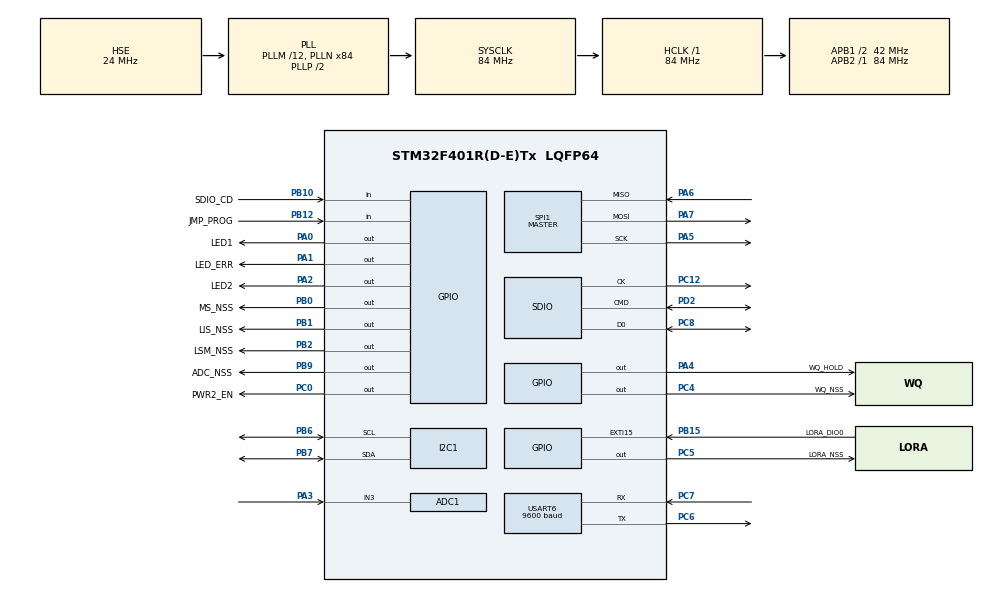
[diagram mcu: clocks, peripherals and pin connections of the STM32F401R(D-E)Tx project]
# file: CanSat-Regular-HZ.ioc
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ADC1.Channel-0\#ChannelRegularConversion=ADC_CHANNEL_3
ADC1.ContinuousConvMode=DISABLE
ADC1.NbrOfConversionFlag=1
ADC1.Rank-0\#ChannelRegularConversion=1
ADC1.Resolution=ADC_RESOLUTION_8B
ADC1.SamplingTime-0\#ChannelRegularConversion=ADC_SAMPLETIME_3CYCLES
ADC1.master=1
Dma.Request0=SDIO_RX
Dma.Request1=SDIO_TX
Dma.SDIO_RX.0.Direction=DMA_PERIPH_TO_MEMORY
Dma.SDIO_RX.0.FIFOMode=DMA_FIFOMODE_ENABLE
Dma.SDIO_RX.0.FIFOThreshold=DMA_FIFO_THRESHOLD_FULL
Dma.SDIO_RX.0.Instance=DMA2_Stream3
Dma.SDIO_RX.0.MemBurst=DMA_MBURST_INC4
Dma.SDIO_RX.0.MemDataAlignment=DMA_MDATAALIGN_WORD
Dma.SDIO_RX.0.MemInc=DMA_MINC_ENABLE
Dma.SDIO_RX.0.Mode=DMA_PFCTRL
Dma.SDIO_RX.0.PeriphBurst=DMA_PBURST_INC4
Dma.SDIO_RX.0.PeriphDataAlignment=DMA_PDATAALIGN_WORD
Dma.SDIO_RX.0.PeriphInc=DMA_PINC_DISABLE
Dma.SDIO_RX.0.Priority=DMA_PRIORITY_LOW
Dma.SDIO_TX.1.Direction=DMA_MEMORY_TO_PERIPH
Dma.SDIO_TX.1.FIFOMode=DMA_FIFOMODE_ENABLE
Dma.SDIO_TX.1.FIFOThreshold=DMA_FIFO_THRESHOLD_FULL
Dma.SDIO_TX.1.Instance=DMA2_Stream6
Dma.SDIO_TX.1.MemBurst=DMA_MBURST_INC4
Dma.SDIO_TX.1.MemDataAlignment=DMA_MDATAALIGN_WORD
Dma.SDIO_TX.1.MemInc=DMA_MINC_ENABLE
Dma.SDIO_TX.1.Mode=DMA_PFCTRL
Dma.SDIO_TX.1.PeriphBurst=DMA_PBURST_INC4
Dma.SDIO_TX.1.PeriphDataAlignment=DMA_PDATAALIGN_WORD
Dma.SDIO_TX.1.PeriphInc=DMA_PINC_DISABLE
Dma.SDIO_TX.1.Priority=DMA_PRIORITY_LOW
FATFS.BSP.number=1
FATFS.USE_DMA_CODE_SD=1
FATFS._FS_TIMEOUT=1000
FATFS0.BSP.STBoard=false
FATFS0.BSP.api=Unknown
FATFS0.BSP.instance=PB10
FATFS0.BSP.ip=GPIO
FATFS0.BSP.mode=Input
FATFS0.BSP.name=Detect_SDIO
FATFS0.BSP.solution=PB10
Mcu.Family=STM32F4
Mcu.Name=STM32F401R(D-E)Tx
Mcu.Package=LQFP64
NVIC.DMA2_Stream3_IRQn=true\:0\:0\:false\:false\:true\:false\:true\:true
NVIC.DMA2_Stream6_IRQn=true\:0\:0\:false\:false\:true\:false\:true\:true
NVIC.EXTI15_10_IRQn=true\:0\:0\:false\:false\:true\:true\:true\:true
NVIC.PriorityGroup=NVIC_PRIORITYGROUP_4
NVIC.SDIO_IRQn=true\:0\:0\:false\:false\:true\:true\:true\:true
NVIC.USART6_IRQn=true\:0\:0\:false\:false\:true\:true\:true\:true
PA0-WKUP.GPIO_Label=LED1
PA0-WKUP.PinState=GPIO_PIN_RESET
PA0-WKUP.Signal=GPIO_Output
PA1.GPIO_Label=LED_ERR
PA1.Signal=GPIO_Output
PA2.GPIO_Label=LED2
PA2.Signal=GPIO_Output
PA3.Signal=ADCx_IN3
PA4.GPIO_Label=WQ_HOLD
PA4.PinState=GPIO_PIN_SET
PA4.Signal=GPIO_Output
PA5.Mode=Full_Duplex_Master
PA5.Signal=SPI1_SCK
PA6.Mode=Full_Duplex_Master
PA6.Signal=SPI1_MISO
PA7.Mode=Full_Duplex_Master
PA7.Signal=SPI1_MOSI
PB0.GPIO_Label=MS_NSS
PB0.GPIO_Speed=GPIO_SPEED_FREQ_VERY_HIGH
PB0.PinState=GPIO_PIN_SET
PB0.Signal=GPIO_Output
PB1.GPIO_Label=LIS_NSS
PB1.GPIO_Speed=GPIO_SPEED_FREQ_VERY_HIGH
PB1.PinState=GPIO_PIN_SET
PB1.Signal=GPIO_Output
PB10.GPIO_Label=SDIO_CD
PB10.Signal=GPIO_Input
PB12.GPIO_Label=JMP_PROG
PB12.Signal=GPIO_Input
PB15.GPIO_Label=LORA_DIO0
PB15.Signal=GPXTI15
PB2.GPIO_Label=LSM_NSS
PB2.GPIO_Speed=GPIO_SPEED_FREQ_VERY_HIGH
PB2.PinState=GPIO_PIN_SET
PB2.Signal=GPIO_Output
PB6.Mode=I2C
PB6.Signal=I2C1_SCL
PB7.Mode=I2C
PB7.Signal=I2C1_SDA
PB9.GPIO_Label=ADC_NSS
PB9.GPIO_Speed=GPIO_SPEED_FREQ_VERY_HIGH
PB9.PinState=GPIO_PIN_SET
PB9.Signal=GPIO_Output
PC0.GPIO_Label=PWR2_EN
PC0.PinState=GPIO_PIN_SET
PC0.Signal=GPIO_Output
PC12.Mode=SD_1_bit
PC12.Signal=SDIO_CK
PC14-OSC32_IN.Mode=LSE-External-Oscillator
PC14-OSC32_IN.Signal=RCC_OSC32_IN
PC15-OSC32_OUT.Mode=LSE-External-Oscillator
PC15-OSC32_OUT.Signal=RCC_OSC32_OUT
PC4.GPIO_Label=WQ_NSS
PC4.GPIO_Speed=GPIO_SPEED_FREQ_VERY_HIGH
PC4.PinState=GPIO_PIN_SET
PC4.Signal=GPIO_Output
PC5.GPIO_Label=LORA_NSS
PC5.GPIO_Speed=GPIO_SPEED_FREQ_VERY_HIGH
PC5.PinState=GPIO_PIN_SET
PC5.Signal=GPIO_Output
PC6.Mode=Asynchronous
PC6.Signal=USART6_TX
PC7.Mode=Asynchronous
PC7.Signal=USART6_RX
PC8.GPIO_PuPd=GPIO_PULLUP
PC8.Mode=SD_1_bit
PC8.Signal=SDIO_D0
PD2.GPIO_PuPd=GPIO_PULLUP
PD2.Mode=SD_1_bit
PD2.Signal=SDIO_CMD
PH0\ -\ OSC_IN.Mode=HSE-External-Oscillator
PH0\ -\ OSC_IN.Signal=RCC_OSC_IN
PH1\ -\ OSC_OUT.Mode=HSE-External-Oscillator
PH1\ -\ OSC_OUT.Signal=RCC_OSC_OUT
ProjectManager.HeapSize=0x200
ProjectManager.StackSize=0x400
ProjectManager.TargetToolchain=STM32CubeIDE
RCC.48MHZClocksFreq_Value=42000000
RCC.AHBFreq_Value=84000000
RCC.APB1CLKDivider=RCC_HCLK_DIV2
RCC.APB1Freq_Value=42000000
RCC.APB1TimFreq_Value=84000000
RCC.APB2Freq_Value=84000000
RCC.APB2TimFreq_Value=84000000
RCC.CortexFreq_Value=84000000
RCC.HCLKFreq_Value=84000000
RCC.HSE_VALUE=24000000
RCC.HSI_VALUE=16000000
RCC.PLLM=12
RCC.PLLN=84
RCC.PLLSourceVirtual=RCC_PLLSOURCE_HSE
RCC.SYSCLKFreq_VALUE=84000000
RCC.SYSCLKSource=RCC_SYSCLKSOURCE_PLLCLK
RCC.VCOOutputFreq_Value=168000000
SDIO.ClockDiv=6
SDIO.HardwareFlowControl=SDIO_HARDWARE_FLOW_CONTROL_ENABLE
SH.ADCx_IN3.0=ADC1_IN3,IN3
SPI1.BaudRatePrescaler=SPI_BAUDRATEPRESCALER_16
SPI1.CLKPhase=SPI_PHASE_1EDGE
SPI1.Direction=SPI_DIRECTION_2LINES
SPI1.Mode=SPI_MODE_MASTER
SPI1.VirtualType=VM_MASTER
USART6.BaudRate=9600
USART6.VirtualMode=VM_ASYNC
VP_FATFS_VS_SDIO.Mode=SDIO
board=custom

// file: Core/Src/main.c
/* USER CODE BEGIN Header */
/**
  ******************************************************************************
  * @file           : main.c
  * @brief          : Main program body
  ******************************************************************************
  * @attention
  *
  * Copyright (c) 2025 STMicroelectronics.
  * All rights reserved.
  *
  * This software is licensed under terms that can be found in the LICENSE file
  * in the root directory of this software component.
  * If no LICENSE file comes with this software, it is provided AS-IS.
  *
  ******************************************************************************
  */
/* USER CODE END Header */
#include "main.h"
#include "fatfs.h"

/* USER CODE BEGIN Includes */
#include "FSM.h"
/* USER CODE END Includes */

ADC_HandleTypeDef hadc1;

I2C_HandleTypeDef hi2c1;

SD_HandleTypeDef hsd;
DMA_HandleTypeDef hdma_sdio_rx;
DMA_HandleTypeDef hdma_sdio_tx;

SPI_HandleTypeDef hspi1;

UART_HandleTypeDef huart6;

void SystemClock_Config(void);
static void MX_GPIO_Init(void);
static void MX_DMA_Init(void);
static void MX_I2C1_Init(void);
static void MX_SPI1_Init(void);
static void MX_ADC1_Init(void);
static void MX_SDIO_SD_Init(void);
static void MX_USART6_UART_Init(void);

int main(void)
{

  /* MCU Configuration--------------------------------------------------------*/

  /* Reset of all peripherals, Initializes the Flash interface and the Systick. */
  HAL_Init();

  /* Configure the system clock */
  SystemClock_Config();

  /* Initialize all configured peripherals */
  MX_GPIO_Init();
  MX_DMA_Init();
  MX_I2C1_Init();
  MX_SPI1_Init();
  MX_ADC1_Init();
  MX_SDIO_SD_Init();
  MX_FATFS_Init();
  MX_USART6_UART_Init();
  /* USER CODE BEGIN 2 */
  FSM_Init();
  /* USER CODE END 2 */

  /* Infinite loop */
  /* USER CODE BEGIN WHILE */
  while (1)
  {
  	FSM_Update();
    /* USER CODE END WHILE */

  }
}

void SystemClock_Config(void)
{
  RCC_OscInitTypeDef RCC_OscInitStruct = {0};
  RCC_ClkInitTypeDef RCC_ClkInitStruct = {0};

  /** Configure the main internal regulator output voltage
  */
  __HAL_RCC_PWR_CLK_ENABLE();
  __HAL_PWR_VOLTAGESCALING_CONFIG(PWR_REGULATOR_VOLTAGE_SCALE2);

  /** Initializes the RCC Oscillators according to the specified parameters
  * in the RCC_OscInitTypeDef structure.
  */
  RCC_OscInitStruct.OscillatorType = RCC_OSCILLATORTYPE_HSE;
  RCC_OscInitStruct.HSEState = RCC_HSE_ON;
  RCC_OscInitStruct.PLL.PLLState = RCC_PLL_ON;
  RCC_OscInitStruct.PLL.PLLSource = RCC_PLLSOURCE_HSE;
  RCC_OscInitStruct.PLL.PLLM = 12;
  RCC_OscInitStruct.PLL.PLLN = 84;
  RCC_OscInitStruct.PLL.PLLP = RCC_PLLP_DIV2;
  RCC_OscInitStruct.PLL.PLLQ = 4;
  if (HAL_RCC_OscConfig(&RCC_OscInitStruct) != HAL_OK)
  {
    Error_Handler();
  }

  /** Initializes the CPU, AHB and APB buses clocks
  */
  RCC_ClkInitStruct.ClockType = RCC_CLOCKTYPE_HCLK|RCC_CLOCKTYPE_SYSCLK
                              |RCC_CLOCKTYPE_PCLK1|RCC_CLOCKTYPE_PCLK2;
  RCC_ClkInitStruct.SYSCLKSource = RCC_SYSCLKSOURCE_PLLCLK;
  RCC_ClkInitStruct.AHBCLKDivider = RCC_SYSCLK_DIV1;
  RCC_ClkInitStruct.APB1CLKDivider = RCC_HCLK_DIV2;
  RCC_ClkInitStruct.APB2CLKDivider = RCC_HCLK_DIV1;

  if (HAL_RCC_ClockConfig(&RCC_ClkInitStruct, FLASH_LATENCY_2) != HAL_OK)
  {
    Error_Handler();
  }
}

static void MX_ADC1_Init(void)
{

  ADC_ChannelConfTypeDef sConfig = {0};

  /** Configure the global features of the ADC (Clock, Resolution, Data Alignment and number of conversion)
  */
  hadc1.Instance = ADC1;
  hadc1.Init.ClockPrescaler = ADC_CLOCK_SYNC_PCLK_DIV4;
  hadc1.Init.Resolution = ADC_RESOLUTION_8B;
  hadc1.Init.ScanConvMode = DISABLE;
  hadc1.Init.ContinuousConvMode = DISABLE;
  hadc1.Init.DiscontinuousConvMode = DISABLE;
  hadc1.Init.ExternalTrigConvEdge = ADC_EXTERNALTRIGCONVEDGE_NONE;
  hadc1.Init.ExternalTrigConv = ADC_SOFTWARE_START;
  hadc1.Init.DataAlign = ADC_DATAALIGN_RIGHT;
  hadc1.Init.NbrOfConversion = 1;
  hadc1.Init.DMAContinuousRequests = DISABLE;
  hadc1.Init.EOCSelection = ADC_EOC_SINGLE_CONV;
  if (HAL_ADC_Init(&hadc1) != HAL_OK)
  {
    Error_Handler();
  }

  /** Configure for the selected ADC regular channel its corresponding rank in the sequencer and its sample time.
  */
  sConfig.Channel = ADC_CHANNEL_3;
  sConfig.Rank = 1;
  sConfig.SamplingTime = ADC_SAMPLETIME_3CYCLES;
  if (HAL_ADC_ConfigChannel(&hadc1, &sConfig) != HAL_OK)
  {
    Error_Handler();
  }

}

static void MX_I2C1_Init(void)
{

  hi2c1.Instance = I2C1;
  hi2c1.Init.ClockSpeed = 100000;
  hi2c1.Init.DutyCycle = I2C_DUTYCYCLE_2;
  hi2c1.Init.OwnAddress1 = 0;
  hi2c1.Init.AddressingMode = I2C_ADDRESSINGMODE_7BIT;
  hi2c1.Init.DualAddressMode = I2C_DUALADDRESS_DISABLE;
  hi2c1.Init.OwnAddress2 = 0;
  hi2c1.Init.GeneralCallMode = I2C_GENERALCALL_DISABLE;
  hi2c1.Init.NoStretchMode = I2C_NOSTRETCH_DISABLE;
  if (HAL_I2C_Init(&hi2c1) != HAL_OK)
  {
    Error_Handler();
  }

}

static void MX_SDIO_SD_Init(void)
{

  hsd.Instance = SDIO;
  hsd.Init.ClockEdge = SDIO_CLOCK_EDGE_RISING;
  hsd.Init.ClockBypass = SDIO_CLOCK_BYPASS_DISABLE;
  hsd.Init.ClockPowerSave = SDIO_CLOCK_POWER_SAVE_DISABLE;
  hsd.Init.BusWide = SDIO_BUS_WIDE_1B;
  hsd.Init.HardwareFlowControl = SDIO_HARDWARE_FLOW_CONTROL_ENABLE;
  hsd.Init.ClockDiv = 6;

}

static void MX_SPI1_Init(void)
{

  /* SPI1 parameter configuration*/
  hspi1.Instance = SPI1;
  hspi1.Init.Mode = SPI_MODE_MASTER;
  hspi1.Init.Direction = SPI_DIRECTION_2LINES;
  hspi1.Init.DataSize = SPI_DATASIZE_8BIT;
  hspi1.Init.CLKPolarity = SPI_POLARITY_LOW;
  hspi1.Init.CLKPhase = SPI_PHASE_1EDGE;
  hspi1.Init.NSS = SPI_NSS_SOFT;
  hspi1.Init.BaudRatePrescaler = SPI_BAUDRATEPRESCALER_16;
  hspi1.Init.FirstBit = SPI_FIRSTBIT_MSB;
  hspi1.Init.TIMode = SPI_TIMODE_DISABLE;
  hspi1.Init.CRCCalculation = SPI_CRCCALCULATION_DISABLE;
  hspi1.Init.CRCPolynomial = 10;
  if (HAL_SPI_Init(&hspi1) != HAL_OK)
  {
    Error_Handler();
  }

}

static void MX_USART6_UART_Init(void)
{

  huart6.Instance = USART6;
  huart6.Init.BaudRate = 9600;
  huart6.Init.WordLength = UART_WORDLENGTH_8B;
  huart6.Init.StopBits = UART_STOPBITS_1;
  huart6.Init.Parity = UART_PARITY_NONE;
  huart6.Init.Mode = UART_MODE_TX_RX;
  huart6.Init.HwFlowCtl = UART_HWCONTROL_NONE;
  huart6.Init.OverSampling = UART_OVERSAMPLING_16;
  if (HAL_UART_Init(&huart6) != HAL_OK)
  {
    Error_Handler();
  }

}

static void MX_DMA_Init(void)
{

  /* DMA controller clock enable */
  __HAL_RCC_DMA2_CLK_ENABLE();

  /* DMA interrupt init */
  /* DMA2_Stream3_IRQn interrupt configuration */
  HAL_NVIC_SetPriority(DMA2_Stream3_IRQn, 0, 0);
  HAL_NVIC_EnableIRQ(DMA2_Stream3_IRQn);
  /* DMA2_Stream6_IRQn interrupt configuration */
  HAL_NVIC_SetPriority(DMA2_Stream6_IRQn, 0, 0);
  HAL_NVIC_EnableIRQ(DMA2_Stream6_IRQn);

}

static void MX_GPIO_Init(void)
{
  GPIO_InitTypeDef GPIO_InitStruct = {0};

  /* GPIO Ports Clock Enable */
  __HAL_RCC_GPIOC_CLK_ENABLE();
  __HAL_RCC_GPIOH_CLK_ENABLE();
  __HAL_RCC_GPIOA_CLK_ENABLE();
  __HAL_RCC_GPIOB_CLK_ENABLE();
  __HAL_RCC_GPIOD_CLK_ENABLE();

  /*Configure GPIO pin Output Level */
  HAL_GPIO_WritePin(GPIOC, PWR2_EN_Pin|WQ_NSS_Pin|LORA_NSS_Pin, GPIO_PIN_SET);

  /*Configure GPIO pin Output Level */
  HAL_GPIO_WritePin(GPIOA, LED1_Pin|LED_ERR_Pin|LED2_Pin, GPIO_PIN_RESET);

  /*Configure GPIO pin Output Level */
  HAL_GPIO_WritePin(WQ_HOLD_GPIO_Port, WQ_HOLD_Pin, GPIO_PIN_SET);

  /*Configure GPIO pin Output Level */
  HAL_GPIO_WritePin(GPIOB, MS_NSS_Pin|LIS_NSS_Pin|LSM_NSS_Pin|ADC_NSS_Pin, GPIO_PIN_SET);

  /*Configure GPIO pin : PWR2_EN_Pin */
  GPIO_InitStruct.Pin = PWR2_EN_Pin;
  GPIO_InitStruct.Mode = GPIO_MODE_OUTPUT_PP;
  GPIO_InitStruct.Pull = GPIO_NOPULL;
  GPIO_InitStruct.Speed = GPIO_SPEED_FREQ_LOW;
  HAL_GPIO_Init(PWR2_EN_GPIO_Port, &GPIO_InitStruct);

  /*Configure GPIO pins : LED1_Pin LED_ERR_Pin LED2_Pin WQ_HOLD_Pin */
  GPIO_InitStruct.Pin = LED1_Pin|LED_ERR_Pin|LED2_Pin|WQ_HOLD_Pin;
  GPIO_InitStruct.Mode = GPIO_MODE_OUTPUT_PP;
  GPIO_InitStruct.Pull = GPIO_NOPULL;
  GPIO_InitStruct.Speed = GPIO_SPEED_FREQ_LOW;
  HAL_GPIO_Init(GPIOA, &GPIO_InitStruct);

  /*Configure GPIO pins : WQ_NSS_Pin LORA_NSS_Pin */
  GPIO_InitStruct.Pin = WQ_NSS_Pin|LORA_NSS_Pin;
  GPIO_InitStruct.Mode = GPIO_MODE_OUTPUT_PP;
  GPIO_InitStruct.Pull = GPIO_NOPULL;
  GPIO_InitStruct.Speed = GPIO_SPEED_FREQ_VERY_HIGH;
  HAL_GPIO_Init(GPIOC, &GPIO_InitStruct);

  /*Configure GPIO pins : MS_NSS_Pin LIS_NSS_Pin LSM_NSS_Pin ADC_NSS_Pin */
  GPIO_InitStruct.Pin = MS_NSS_Pin|LIS_NSS_Pin|LSM_NSS_Pin|ADC_NSS_Pin;
  GPIO_InitStruct.Mode = GPIO_MODE_OUTPUT_PP;
  GPIO_InitStruct.Pull = GPIO_NOPULL;
  GPIO_InitStruct.Speed = GPIO_SPEED_FREQ_VERY_HIGH;
  HAL_GPIO_Init(GPIOB, &GPIO_InitStruct);

  /*Configure GPIO pins : SDIO_CD_Pin JMP_PROG_Pin */
  GPIO_InitStruct.Pin = SDIO_CD_Pin|JMP_PROG_Pin;
  GPIO_InitStruct.Mode = GPIO_MODE_INPUT;
  GPIO_InitStruct.Pull = GPIO_NOPULL;
  HAL_GPIO_Init(GPIOB, &GPIO_InitStruct);

  /*Configure GPIO pin : LORA_DIO0_Pin */
  GPIO_InitStruct.Pin = LORA_DIO0_Pin;
  GPIO_InitStruct.Mode = GPIO_MODE_IT_RISING;
  GPIO_InitStruct.Pull = GPIO_NOPULL;
  HAL_GPIO_Init(LORA_DIO0_GPIO_Port, &GPIO_InitStruct);

  /* EXTI interrupt init*/
  HAL_NVIC_SetPriority(EXTI15_10_IRQn, 0, 0);
  HAL_NVIC_EnableIRQ(EXTI15_10_IRQn);

}

void Error_Handler(void)
{
  __disable_irq();
  while (1)
  {
  }
}
